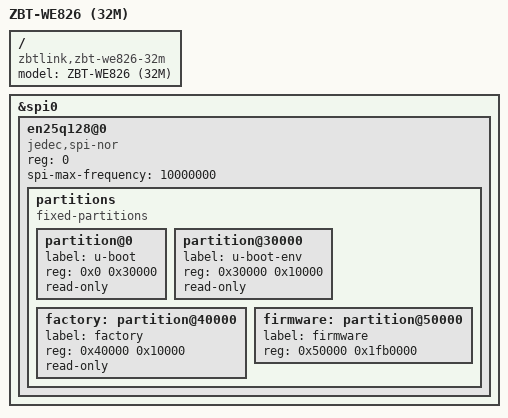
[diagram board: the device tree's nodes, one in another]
/dts-v1/;

#include "ZBT-WE826.dtsi"

/ {
	compatible = "zbtlink,zbt-we826-32m", "zbtlink,zbt-we826", "ralink,mt7620a-soc";
	model = "ZBT-WE826 (32M)";
};

&spi0 {
	status = "okay";

	en25q128@0 {
		compatible = "jedec,spi-nor";
		reg = <0>;
		spi-max-frequency = <10000000>;

		partitions {
			compatible = "fixed-partitions";
			#address-cells = <1>;
			#size-cells = <1>;

			partition@0 {
				label = "u-boot";
				reg = <0x0 0x30000>;
				read-only;
			};

			partition@30000 {
				label = "u-boot-env";
				reg = <0x30000 0x10000>;
				read-only;
			};

			factory: partition@40000 {
				label = "factory";
				reg = <0x40000 0x10000>;
				read-only;
			};

			firmware: partition@50000 {
				label = "firmware";
				reg = <0x50000 0x1fb0000>;
			};
		};
	};
};
